AUTOSAR XML (schema 4-3-1)
standard types defined: Double, float64
package /Components
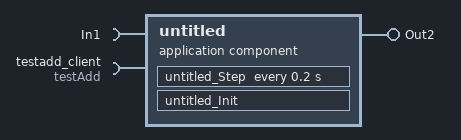
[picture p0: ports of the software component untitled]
  application sw component type untitled
    require port In1: nonqueued-receiver-com-spec{data-element=In1, init-value=0}, required-interface=In1
    provide port Out2: nonqueued-sender-com-spec{data-element=Out2, init-value=0}, provided-interface=Out2
    require port testadd_client: required-interface=testAdd
    behavior untitled_IB: handle-termination-and-restart=NO-SUPPORT
      timing event Event_untitled_Step: start-on-event=untitled_Step, period=0.2
      runnable untitled_Init
      runnable untitled_Step
        data-read-access:
          access IN_In1_In1: accessed-variable=In1.In1
        data-write-access:
          access OUT_Out2_Out2: accessed-variable=Out2.Out2
        sync call SC_testadd_client_testAdd: operation=testadd_client.testAdd, timeout=1.0E-06
package /Components/SwcImplementations
  swc implementation untitled_Impl: programming-language=C, sw-version=1.9.1, used-code-generator=Embedded Coder 7.4 (R2020a) 18-Nov-2019, vendor-id=0, behavior=untitled_IB
    code-descriptors:
      code Code
        artifact-descriptors:
          short-label=client_c, category=SWSRC
          short-label=client_h, category=SWHDR
          short-label=client_private_h, category=SWHDR
          short-label=client_types_h, category=SWHDR
          short-label=rtwtypes_h, category=SWHDR
    resource consumption RsrcCons_client
package /Interfaces
  sender receiver interface In1
    data In1: category=VALUE, sw-calibration-access=READ-ONLY, type=Double
  client server interface testAdd
    operation testAdd
      arg u: category=VALUE, sw-calibration-access=READ-ONLY, type=Double, direction=IN
      arg y: category=VALUE, sw-calibration-access=READ-ONLY, type=Double, direction=OUT
  sender receiver interface Out2
    data Out2: category=VALUE, sw-calibration-access=READ-ONLY, type=Double
